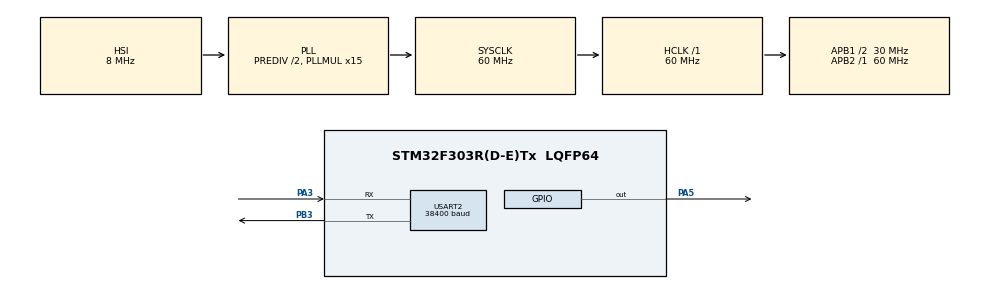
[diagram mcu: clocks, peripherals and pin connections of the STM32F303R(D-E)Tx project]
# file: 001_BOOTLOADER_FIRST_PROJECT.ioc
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Mcu.Family=STM32F3
Mcu.Name=STM32F303R(D-E)Tx
Mcu.Package=LQFP64
NVIC.PriorityGroup=NVIC_PRIORITYGROUP_4
PA3.Mode=Asynchronous
PA3.Signal=USART2_RX
PA5.Signal=GPIO_Output
PB3.Mode=Asynchronous
PB3.Signal=USART2_TX
PC10.Signal=USART3_TX
PC11.Signal=USART3_RX
ProjectManager.HeapSize=0x200
ProjectManager.StackSize=0x400
ProjectManager.TargetToolchain=STM32CubeIDE
RCC.AHBFreq_Value=60000000
RCC.APB1CLKDivider=RCC_HCLK_DIV2
RCC.APB1Freq_Value=30000000
RCC.APB1TimFreq_Value=60000000
RCC.APB2Freq_Value=60000000
RCC.APB2TimFreq_Value=60000000
RCC.CortexFreq_Value=60000000
RCC.HCLKFreq_Value=60000000
RCC.HSE_VALUE=8000000
RCC.HSI_VALUE=8000000
RCC.LSE_VALUE=32768
RCC.PLLDivider=RCC_PREDIV_DIV2
RCC.PLLMUL=RCC_PLL_MUL15
RCC.SYSCLKFreq_VALUE=60000000
RCC.SYSCLKSourceVirtual=RCC_SYSCLKSOURCE_PLLCLK
RCC.USBFreq_Value=60000000
USART2.BaudRate=38400
USART2.VirtualMode-Asynchronous=VM_ASYNC
VP_CRC_VS_CRC.Mode=CRC_Activate
board=custom

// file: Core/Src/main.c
/* USER CODE BEGIN Header */
/**
  ******************************************************************************
  * @file           : main.c
  * @brief          : Main program body
  ******************************************************************************
  * @attention
  *
  * Copyright (c) 2025 STMicroelectronics.
  * All rights reserved.
  *
  * This software is licensed under terms that can be found in the LICENSE file
  * in the root directory of this software component.
  * If no LICENSE file comes with this software, it is provided AS-IS.
  *
  ******************************************************************************
  */
/* USER CODE END Header */
#include "main.h"

/* USER CODE BEGIN Includes */

#include "stdarg.h"
#include "stdio.h"
#include "string.h"

/* USER CODE END Includes */

/* USER CODE BEGIN PD */

#define DEBUG_UART_PORT &huart2

/* USER CODE END PD */

CRC_HandleTypeDef hcrc;

UART_HandleTypeDef huart2;

void SystemClock_Config(void);
static void MX_GPIO_Init(void);
static void MX_CRC_Init(void);
static void MX_USART2_UART_Init(void);

/* USER CODE BEGIN 0 */

void print_message(char* format, ...){

	char coming_message[100];

	va_list va_list;
	va_start(va_list, format);
	vsprintf(coming_message, format, va_list);
	HAL_UART_Transmit(DEBUG_UART_PORT, (uint8_t*)coming_message, strlen(coming_message), HAL_MAX_DELAY);
	va_end(va_list);
}

/* USER CODE END 0 */

int main(void)
{

  /* USER CODE BEGIN 1 */

	char my_message[] = "Test mesaji...\n";

  /* USER CODE END 1 */

  /* MCU Configuration--------------------------------------------------------*/

  /* Reset of all peripherals, Initializes the Flash interface and the Systick. */
  HAL_Init();

  /* Configure the system clock */
  SystemClock_Config();

  /* Initialize all configured peripherals */
  MX_GPIO_Init();
  MX_CRC_Init();
  MX_USART2_UART_Init();

  /* Infinite loop */
  while (1)
  {

    /* USER CODE BEGIN 3 */
	  //HAL_UART_Transmit(&huart2, (uint8_t*)my_message, sizeof(my_message), HAL_MAX_DELAY);
	  HAL_GPIO_TogglePin(GPIOA, GPIO_PIN_5);
	  print_message("Yazilan metodun testi %d %d\n", 1, 2);
	  HAL_Delay(500);
  }
  /* USER CODE END 3 */
}

void SystemClock_Config(void)
{
  RCC_OscInitTypeDef RCC_OscInitStruct = {0};
  RCC_ClkInitTypeDef RCC_ClkInitStruct = {0};
  RCC_PeriphCLKInitTypeDef PeriphClkInit = {0};

  /** Initializes the RCC Oscillators according to the specified parameters
  * in the RCC_OscInitTypeDef structure.
  */
  RCC_OscInitStruct.OscillatorType = RCC_OSCILLATORTYPE_HSI;
  RCC_OscInitStruct.HSIState = RCC_HSI_ON;
  RCC_OscInitStruct.HSICalibrationValue = RCC_HSICALIBRATION_DEFAULT;
  RCC_OscInitStruct.PLL.PLLState = RCC_PLL_ON;
  RCC_OscInitStruct.PLL.PLLSource = RCC_PLLSOURCE_HSI;
  RCC_OscInitStruct.PLL.PLLMUL = RCC_PLL_MUL15;
  RCC_OscInitStruct.PLL.PREDIV = RCC_PREDIV_DIV2;
  if (HAL_RCC_OscConfig(&RCC_OscInitStruct) != HAL_OK)
  {
    Error_Handler();
  }

  /** Initializes the CPU, AHB and APB buses clocks
  */
  RCC_ClkInitStruct.ClockType = RCC_CLOCKTYPE_HCLK|RCC_CLOCKTYPE_SYSCLK
                              |RCC_CLOCKTYPE_PCLK1|RCC_CLOCKTYPE_PCLK2;
  RCC_ClkInitStruct.SYSCLKSource = RCC_SYSCLKSOURCE_PLLCLK;
  RCC_ClkInitStruct.AHBCLKDivider = RCC_SYSCLK_DIV1;
  RCC_ClkInitStruct.APB1CLKDivider = RCC_HCLK_DIV2;
  RCC_ClkInitStruct.APB2CLKDivider = RCC_HCLK_DIV1;

  if (HAL_RCC_ClockConfig(&RCC_ClkInitStruct, FLASH_LATENCY_2) != HAL_OK)
  {
    Error_Handler();
  }
  PeriphClkInit.PeriphClockSelection = RCC_PERIPHCLK_USART2;
  PeriphClkInit.Usart2ClockSelection = RCC_USART2CLKSOURCE_PCLK1;
  if (HAL_RCCEx_PeriphCLKConfig(&PeriphClkInit) != HAL_OK)
  {
    Error_Handler();
  }
}

static void MX_CRC_Init(void)
{

  hcrc.Instance = CRC;
  hcrc.Init.DefaultPolynomialUse = DEFAULT_POLYNOMIAL_ENABLE;
  hcrc.Init.DefaultInitValueUse = DEFAULT_INIT_VALUE_ENABLE;
  hcrc.Init.InputDataInversionMode = CRC_INPUTDATA_INVERSION_NONE;
  hcrc.Init.OutputDataInversionMode = CRC_OUTPUTDATA_INVERSION_DISABLE;
  hcrc.InputDataFormat = CRC_INPUTDATA_FORMAT_BYTES;
  if (HAL_CRC_Init(&hcrc) != HAL_OK)
  {
    Error_Handler();
  }

}

static void MX_USART2_UART_Init(void)
{

  huart2.Instance = USART2;
  huart2.Init.BaudRate = 38400;
  huart2.Init.WordLength = UART_WORDLENGTH_8B;
  huart2.Init.StopBits = UART_STOPBITS_1;
  huart2.Init.Parity = UART_PARITY_NONE;
  huart2.Init.Mode = UART_MODE_TX_RX;
  huart2.Init.HwFlowCtl = UART_HWCONTROL_NONE;
  huart2.Init.OverSampling = UART_OVERSAMPLING_16;
  huart2.Init.OneBitSampling = UART_ONE_BIT_SAMPLE_DISABLE;
  huart2.AdvancedInit.AdvFeatureInit = UART_ADVFEATURE_NO_INIT;
  if (HAL_UART_Init(&huart2) != HAL_OK)
  {
    Error_Handler();
  }

}

static void MX_GPIO_Init(void)
{
  GPIO_InitTypeDef GPIO_InitStruct = {0};

  /* GPIO Ports Clock Enable */
  __HAL_RCC_GPIOA_CLK_ENABLE();
  __HAL_RCC_GPIOC_CLK_ENABLE();
  __HAL_RCC_GPIOB_CLK_ENABLE();

  /*Configure GPIO pin Output Level */
  HAL_GPIO_WritePin(GPIOA, GPIO_PIN_5, GPIO_PIN_RESET);

  /*Configure GPIO pin : PA5 */
  GPIO_InitStruct.Pin = GPIO_PIN_5;
  GPIO_InitStruct.Mode = GPIO_MODE_OUTPUT_PP;
  GPIO_InitStruct.Pull = GPIO_NOPULL;
  GPIO_InitStruct.Speed = GPIO_SPEED_FREQ_LOW;
  HAL_GPIO_Init(GPIOA, &GPIO_InitStruct);

  /*Configure GPIO pins : PC10 PC11 */
  GPIO_InitStruct.Pin = GPIO_PIN_10|GPIO_PIN_11;
  GPIO_InitStruct.Mode = GPIO_MODE_AF_PP;
  GPIO_InitStruct.Pull = GPIO_NOPULL;
  GPIO_InitStruct.Speed = GPIO_SPEED_FREQ_HIGH;
  GPIO_InitStruct.Alternate = GPIO_AF7_USART3;
  HAL_GPIO_Init(GPIOC, &GPIO_InitStruct);

}

void Error_Handler(void)
{
  __disable_irq();
  while (1)
  {
  }
}
